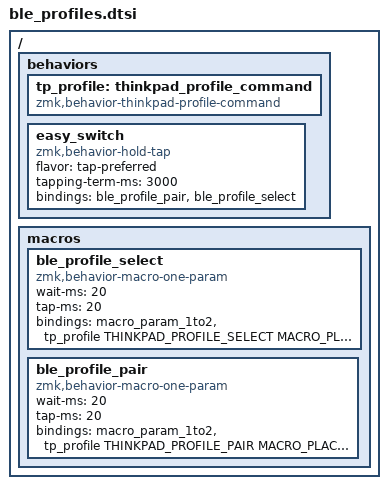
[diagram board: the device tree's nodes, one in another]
#include <dt-bindings/thinkpad/profile.h>

/*
 * Shared Logitech-style three-host Easy-Switch behavior.
 *
 * SPDX-License-Identifier: MIT
 */

/ {
    behaviors {
        tp_profile: thinkpad_profile_command {
            compatible = "zmk,behavior-thinkpad-profile-command";
            #binding-cells = <2>;
        };

        easy_switch: easy_switch {
            compatible = "zmk,behavior-hold-tap";
            #binding-cells = <2>;
            flavor = "tap-preferred";
            tapping-term-ms = <3000>;
            bindings = <&ble_profile_pair>, <&ble_profile_select>;
        };
    };

    macros {
        ble_profile_select: ble_profile_select {
            compatible = "zmk,behavior-macro-one-param";
            #binding-cells = <1>;
            wait-ms = <20>;
            tap-ms = <20>;
            bindings = <
                &macro_param_1to2 &tp_profile THINKPAD_PROFILE_SELECT MACRO_PLACEHOLDER
            >;
        };

        ble_profile_pair: ble_profile_pair {
            compatible = "zmk,behavior-macro-one-param";
            #binding-cells = <1>;
            wait-ms = <20>;
            tap-ms = <20>;
            bindings = <
                &macro_param_1to2 &tp_profile THINKPAD_PROFILE_PAIR MACRO_PLACEHOLDER
            >;
        };
    };
};
